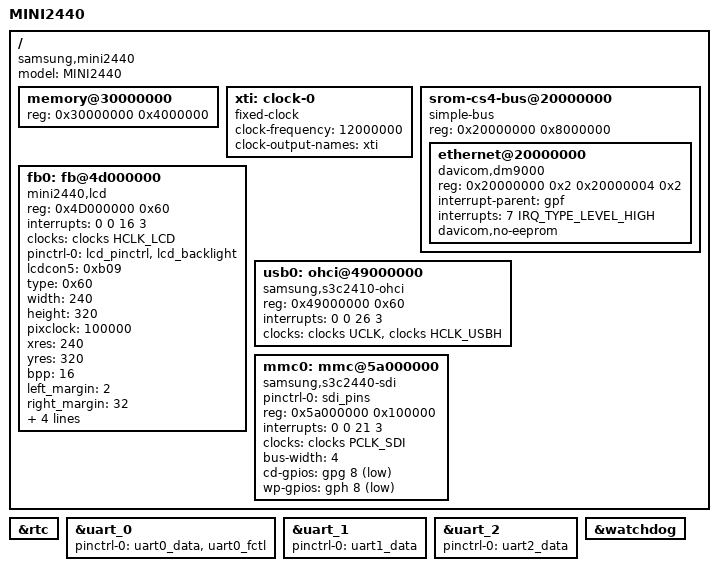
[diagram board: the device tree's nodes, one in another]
// SPDX-License-Identifier: GPL-2.0
/*
 * Samsung SMDK2416 board device tree source
 *
 * Copyright (c) 2013 Heiko Stuebner <heiko@sntech.de>
 */

/dts-v1/;
#include <dt-bindings/interrupt-controller/irq.h>
#include <dt-bindings/gpio/gpio.h>
#include "s3c2440.dtsi"

/ {
	model = "MINI2440";
	compatible = "samsung,mini2440", "samsung,s3c2440";

	memory@30000000 {
		device_type = "memory";
		reg =  <0x30000000 0x4000000>;
	};

	xti: clock-0 {
		compatible = "fixed-clock";
		clock-frequency = <12000000>;
		clock-output-names = "xti";
		#clock-cells = <0>;
	};

        srom-cs4-bus@20000000 {
                compatible = "simple-bus";
                #address-cells = <1>;
                #size-cells = <1>;
                reg = <0x20000000 0x8000000>;
                ranges;

                ethernet@20000000 {
                        compatible = "davicom,dm9000";
                        reg = <0x20000000 0x2 0x20000004 0x2>;
                        interrupt-parent = <&gpf>;
                        interrupts = <7 IRQ_TYPE_LEVEL_HIGH>;
                        davicom,no-eeprom;
                };
        };

        fb0: fb@4d000000{
             compatible = "mini2440,lcd";
             reg = <0x4D000000 0x60>;
             interrupts = <0 0 16 3>;
             clocks = <&clocks HCLK_LCD>;
             clock-names = "lcd";
             pinctrl-names = "default";
             pinctrl-0 = <&lcd_pinctrl &lcd_backlight>;
             status = "okay";

             lcdcon5 = <0xb09>;
             type = <0x60>;
             width = /bits/ 16 <240>;
             height = /bits/ 16 <320>;
             pixclock = <100000>;
             xres = /bits/ 16 <240>;
             yres = /bits/ 16 <320>;
             bpp = /bits/ 16 <16>;
             left_margin = /bits/ 16 <2>;
             right_margin =/bits/ 16  <32>;
             hsync_len = /bits/ 16 <41>;
             upper_margin = /bits/ 16 <2>;
             lower_margin = /bits/ 16 <2>;
             vsync_len = /bits/ 16 <10>;
        };

        usb0: ohci@49000000 {
              compatible = "samsung,s3c2410-ohci";
              reg = <0x49000000 0x60>;
              interrupts = <0 0 26 3>;
              clocks = <&clocks UCLK>, <&clocks HCLK_USBH>;
              clock-names = "usb-bus-host", "usb-host";
	      status = "okay";
        };

        mmc0: mmc@5a000000 {
	      compatible = "samsung,s3c2440-sdi";
	      pinctrl-names = "default";
	      pinctrl-0 = <&sdi_pins>;
	      reg = <0x5a000000 0x100000>;
	      interrupts = <0 0 21 3>;
	      clocks = <&clocks PCLK_SDI>;
	      clock-names = "sdi";
	      bus-width = <4>;
	      cd-gpios = <&gpg 8 GPIO_ACTIVE_LOW>;
	      wp-gpios = <&gph 8 GPIO_ACTIVE_LOW>;
        };
};

&rtc {
	status = "okay";
};

&uart_0 {
	status = "okay";
	pinctrl-names = "default";
	pinctrl-0 = <&uart0_data>, <&uart0_fctl>;
};

&uart_1 {
	status = "okay";
	pinctrl-names = "default";
	pinctrl-0 = <&uart1_data>;
};

&uart_2 {
	status = "okay";
	pinctrl-names = "default";
	pinctrl-0 = <&uart2_data>;
};

&watchdog {
	status = "okay";
};
